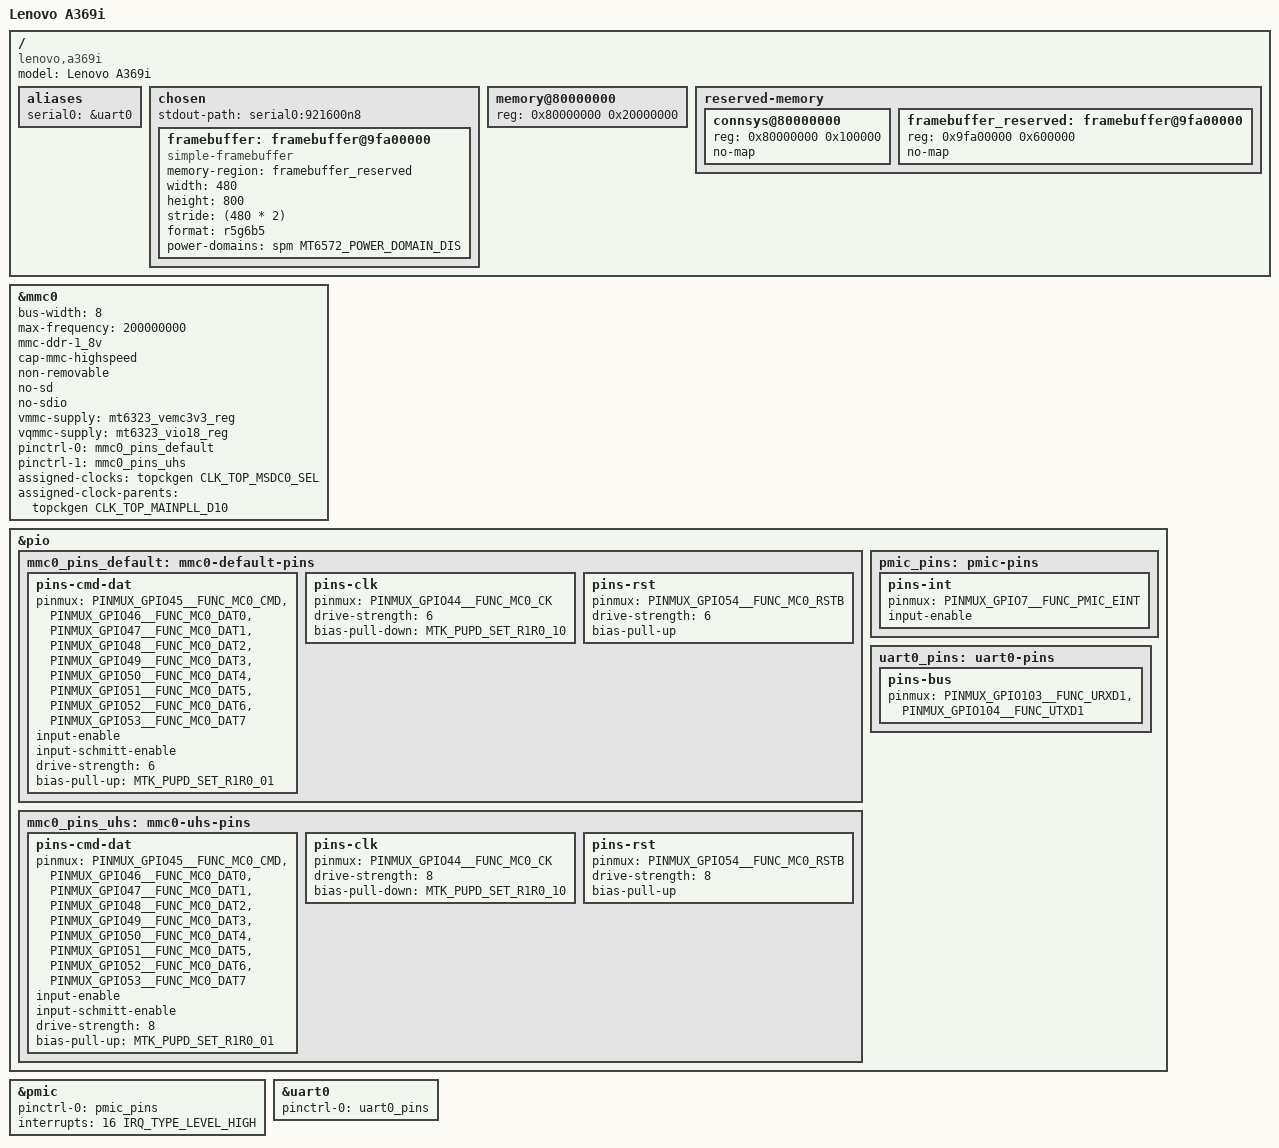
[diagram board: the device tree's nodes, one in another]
// SPDX-License-Identifier: GPL-2.0
/*
 * Copyright (c) 2025 Max Shevchenko <wctrl@proton.me>
 */

/dts-v1/;
#include <dt-bindings/gpio/gpio.h>
#include "mt6572.dtsi"
#include "mt6323.dtsi"

/ {
	model = "Lenovo A369i";
	compatible = "lenovo,a369i", "mediatek,mt6572";

	aliases {
		serial0 = &uart0;
	};

	chosen {
		#address-cells = <1>;
		#size-cells = <1>;
		stdout-path = "serial0:921600n8";

		framebuffer: framebuffer@9fa00000 {
			compatible = "simple-framebuffer";
			memory-region = <&framebuffer_reserved>;
			width = <480>;
			height = <800>;
			stride = <(480 * 2)>;
			format = "r5g6b5";
			power-domains = <&spm MT6572_POWER_DOMAIN_DIS>;
		};
	};

	memory@80000000 {
		device_type = "memory";
		reg = <0x80000000 0x20000000>;
	};

	reserved-memory {
		#address-cells = <1>;
		#size-cells = <1>;
		ranges;

		connsys@80000000 {
			reg = <0x80000000 0x100000>;
			no-map;
		};

		framebuffer_reserved: framebuffer@9fa00000 {
			reg = <0x9fa00000 0x600000>;
			no-map;
		};
	};
};

&mmc0 {
	bus-width = <8>;
	max-frequency = <200000000>;
	mmc-ddr-1_8v;
	cap-mmc-highspeed;
	non-removable;
	no-sd;
	no-sdio;

	vmmc-supply = <&mt6323_vemc3v3_reg>;
	vqmmc-supply = <&mt6323_vio18_reg>;
	pinctrl-0 = <&mmc0_pins_default>;
	pinctrl-1 = <&mmc0_pins_uhs>;
	pinctrl-names = "default", "state_uhs";

	assigned-clocks = <&topckgen CLK_TOP_MSDC0_SEL>;
	assigned-clock-parents = <&topckgen CLK_TOP_MAINPLL_D10>;

	status = "okay";
};

&pio {
	mmc0_pins_default: mmc0-default-pins {
		pins-cmd-dat {
			pinmux = <PINMUX_GPIO45__FUNC_MC0_CMD>,
				 <PINMUX_GPIO46__FUNC_MC0_DAT0>,
				 <PINMUX_GPIO47__FUNC_MC0_DAT1>,
				 <PINMUX_GPIO48__FUNC_MC0_DAT2>,
				 <PINMUX_GPIO49__FUNC_MC0_DAT3>,
				 <PINMUX_GPIO50__FUNC_MC0_DAT4>,
				 <PINMUX_GPIO51__FUNC_MC0_DAT5>,
				 <PINMUX_GPIO52__FUNC_MC0_DAT6>,
				 <PINMUX_GPIO53__FUNC_MC0_DAT7>;
			input-enable;
			input-schmitt-enable;
			drive-strength = <6>;
			bias-pull-up = <MTK_PUPD_SET_R1R0_01>;
		};

		pins-clk {
			pinmux = <PINMUX_GPIO44__FUNC_MC0_CK>;
			drive-strength = <6>;
			bias-pull-down = <MTK_PUPD_SET_R1R0_10>;
		};

		pins-rst {
			pinmux = <PINMUX_GPIO54__FUNC_MC0_RSTB>;
			drive-strength = <6>;
			bias-pull-up;
		};
	};

	mmc0_pins_uhs: mmc0-uhs-pins {
		pins-cmd-dat {
			pinmux = <PINMUX_GPIO45__FUNC_MC0_CMD>,
				 <PINMUX_GPIO46__FUNC_MC0_DAT0>,
				 <PINMUX_GPIO47__FUNC_MC0_DAT1>,
				 <PINMUX_GPIO48__FUNC_MC0_DAT2>,
				 <PINMUX_GPIO49__FUNC_MC0_DAT3>,
				 <PINMUX_GPIO50__FUNC_MC0_DAT4>,
				 <PINMUX_GPIO51__FUNC_MC0_DAT5>,
				 <PINMUX_GPIO52__FUNC_MC0_DAT6>,
				 <PINMUX_GPIO53__FUNC_MC0_DAT7>;
			input-enable;
			input-schmitt-enable;
			drive-strength = <8>;
			bias-pull-up = <MTK_PUPD_SET_R1R0_01>;
		};

		pins-clk {
			pinmux = <PINMUX_GPIO44__FUNC_MC0_CK>;
			drive-strength = <8>;
			bias-pull-down = <MTK_PUPD_SET_R1R0_10>;
		};

		pins-rst {
			pinmux = <PINMUX_GPIO54__FUNC_MC0_RSTB>;
			drive-strength = <8>;
			bias-pull-up;
		};
	};

	pmic_pins: pmic-pins {
		pins-int {
			pinmux = <PINMUX_GPIO7__FUNC_PMIC_EINT>;
			input-enable;
		};
	};

	uart0_pins: uart0-pins {
		pins-bus {
			pinmux = <PINMUX_GPIO103__FUNC_URXD1>,
				 <PINMUX_GPIO104__FUNC_UTXD1>;
		};
	};
};

&pmic {
	pinctrl-0 = <&pmic_pins>;
	pinctrl-names = "default";

	interrupts = <16 IRQ_TYPE_LEVEL_HIGH>;
};

&uart0 {
	pinctrl-0 = <&uart0_pins>;
	pinctrl-names = "default";

	status = "okay";
};
